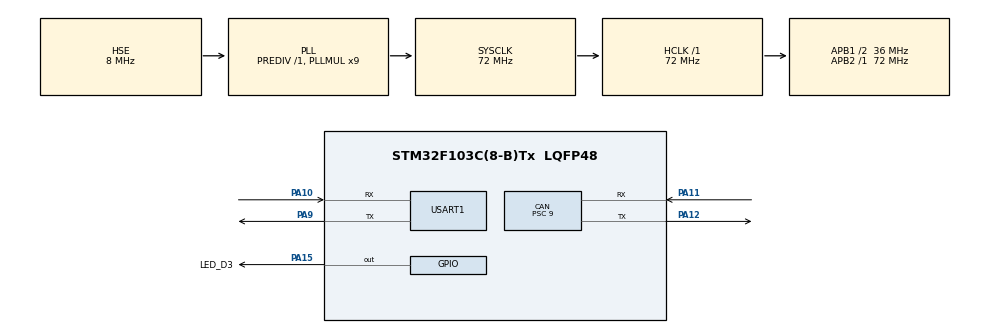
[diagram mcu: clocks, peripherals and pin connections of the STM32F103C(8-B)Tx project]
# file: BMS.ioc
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CAN.BS1=CAN_BS1_2TQ
CAN.BS2=CAN_BS2_5TQ
CAN.CalculateBaudRate=500000
CAN.CalculateTimeBit=2000
CAN.CalculateTimeQuantum=250.0
CAN.Prescaler=9
FREERTOS.Tasks01=defaultTask,24,128,StartDefaultTask,Default,NULL,Dynamic,NULL,NULL
FREERTOS.configTOTAL_HEAP_SIZE=10240
Mcu.Family=STM32F1
Mcu.Name=STM32F103C(8-B)Tx
Mcu.Package=LQFP48
NVIC.PriorityGroup=NVIC_PRIORITYGROUP_4
NVIC.TIM3_IRQn=true\:15\:0\:false\:false\:true\:false\:false\:true\:true
NVIC.TimeBase=TIM3_IRQn
NVIC.TimeBaseIP=TIM3
NVIC.USB_LP_CAN1_RX0_IRQn=true\:5\:0\:true\:false\:true\:true\:true\:true\:true
PA10.Mode=Asynchronous
PA10.Signal=USART1_RX
PA11.Mode=CAN_Activate
PA11.Signal=CAN_RX
PA12.Mode=CAN_Activate
PA12.Signal=CAN_TX
PA13.Mode=Serial_Wire
PA13.Signal=SYS_JTMS-SWDIO
PA14.Mode=Serial_Wire
PA14.Signal=SYS_JTCK-SWCLK
PA15.GPIO_Label=LED_D3
PA15.GPIO_Speed=GPIO_SPEED_FREQ_LOW
PA15.PinState=GPIO_PIN_SET
PA15.Signal=GPIO_Output
PA9.Mode=Asynchronous
PA9.Signal=USART1_TX
PD0-OSC_IN.Mode=HSE-External-Oscillator
PD0-OSC_IN.Signal=RCC_OSC_IN
PD1-OSC_OUT.Mode=HSE-External-Oscillator
PD1-OSC_OUT.Signal=RCC_OSC_OUT
ProjectManager.HeapSize=0x200
ProjectManager.StackSize=0x400
ProjectManager.TargetToolchain=MDK-ARM V5.32
RCC.AHBFreq_Value=72000000
RCC.APB1CLKDivider=RCC_HCLK_DIV2
RCC.APB1Freq_Value=36000000
RCC.APB1TimFreq_Value=72000000
RCC.APB2Freq_Value=72000000
RCC.APB2TimFreq_Value=72000000
RCC.HCLKFreq_Value=72000000
RCC.PLLMUL=RCC_PLL_MUL9
RCC.PLLSourceVirtual=RCC_PLLSOURCE_HSE
RCC.SYSCLKFreq_VALUE=72000000
RCC.SYSCLKSource=RCC_SYSCLKSOURCE_PLLCLK
RCC.USBFreq_Value=72000000
USART1.VirtualMode=VM_ASYNC
VP_FREERTOS_VS_CMSIS_V2.Mode=CMSIS_V2
VP_SYS_VS_tim3.Mode=TIM3
board=custom

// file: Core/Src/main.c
/* USER CODE BEGIN Header */
/**
  ******************************************************************************
  * @file           : main.c
  * @brief          : Main program body
  ******************************************************************************
  * @attention
  *
  * Copyright (c) 2026 STMicroelectronics.
  * All rights reserved.
  *
  * This software is licensed under terms that can be found in the LICENSE file
  * in the root directory of this software component.
  * If no LICENSE file comes with this software, it is provided AS-IS.
  *
  ******************************************************************************
  */
/* USER CODE END Header */
#include "main.h"
#include "cmsis_os.h"
#include "can.h"
#include "usart.h"
#include "gpio.h"

void SystemClock_Config(void);
void MX_FREERTOS_Init(void);

int main(void)
{

  /* MCU Configuration--------------------------------------------------------*/

  /* Reset of all peripherals, Initializes the Flash interface and the Systick. */
  HAL_Init();

  /* Configure the system clock */
  SystemClock_Config();

  /* Initialize all configured peripherals */
  MX_GPIO_Init();
  MX_USART1_UART_Init();
  MX_CAN_Init();

  /* Init scheduler */
  osKernelInitialize();

  /* Call init function for freertos objects (in cmsis_os2.c) */
  MX_FREERTOS_Init();

  /* Start scheduler */
  osKernelStart();

  /* We should never get here as control is now taken by the scheduler */

  /* Infinite loop */
  while (1)
  {

  }
}

void SystemClock_Config(void)
{
  RCC_OscInitTypeDef RCC_OscInitStruct = {0};
  RCC_ClkInitTypeDef RCC_ClkInitStruct = {0};

  /** Initializes the RCC Oscillators according to the specified parameters
  * in the RCC_OscInitTypeDef structure.
  */
  RCC_OscInitStruct.OscillatorType = RCC_OSCILLATORTYPE_HSE;
  RCC_OscInitStruct.HSEState = RCC_HSE_ON;
  RCC_OscInitStruct.HSEPredivValue = RCC_HSE_PREDIV_DIV1;
  RCC_OscInitStruct.HSIState = RCC_HSI_ON;
  RCC_OscInitStruct.PLL.PLLState = RCC_PLL_ON;
  RCC_OscInitStruct.PLL.PLLSource = RCC_PLLSOURCE_HSE;
  RCC_OscInitStruct.PLL.PLLMUL = RCC_PLL_MUL9;
  if (HAL_RCC_OscConfig(&RCC_OscInitStruct) != HAL_OK)
  {
    Error_Handler();
  }

  /** Initializes the CPU, AHB and APB buses clocks
  */
  RCC_ClkInitStruct.ClockType = RCC_CLOCKTYPE_HCLK|RCC_CLOCKTYPE_SYSCLK
                              |RCC_CLOCKTYPE_PCLK1|RCC_CLOCKTYPE_PCLK2;
  RCC_ClkInitStruct.SYSCLKSource = RCC_SYSCLKSOURCE_PLLCLK;
  RCC_ClkInitStruct.AHBCLKDivider = RCC_SYSCLK_DIV1;
  RCC_ClkInitStruct.APB1CLKDivider = RCC_HCLK_DIV2;
  RCC_ClkInitStruct.APB2CLKDivider = RCC_HCLK_DIV1;

  if (HAL_RCC_ClockConfig(&RCC_ClkInitStruct, FLASH_LATENCY_2) != HAL_OK)
  {
    Error_Handler();
  }
}

void HAL_TIM_PeriodElapsedCallback(TIM_HandleTypeDef *htim)
{
  if (htim->Instance == TIM3) {
    HAL_IncTick();
  }
}

void Error_Handler(void)
{
  __disable_irq();
  while (1)
  {
  }
}

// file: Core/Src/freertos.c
/* USER CODE BEGIN Header */
/**
  ******************************************************************************
  * File Name          : freertos.c
  * Description        : Code for freertos applications
  ******************************************************************************
  * @attention
  *
  * Copyright (c) 2026 STMicroelectronics.
  * All rights reserved.
  *
  * This software is licensed under terms that can be found in the LICENSE file
  * in the root directory of this software component.
  * If no LICENSE file comes with this software, it is provided AS-IS.
  *
  ******************************************************************************
  */
/* USER CODE END Header */

#include "FreeRTOS.h"
#include "task.h"
#include "main.h"
#include "cmsis_os.h"

/* USER CODE BEGIN Includes */
#include "TaskInit.h"
/* USER CODE END Includes */

/* Definitions for defaultTask */
osThreadId_t defaultTaskHandle;
const osThreadAttr_t defaultTask_attributes = {
  .name = "defaultTask",
  .stack_size = 128 * 4,
  .priority = (osPriority_t) osPriorityNormal,
};

void StartDefaultTask(void *argument);

void MX_FREERTOS_Init(void); /* (MISRA C 2004 rule 8.1) */

void MX_FREERTOS_Init(void) {

  /* Create the thread(s) */
  /* creation of defaultTask */
  defaultTaskHandle = osThreadNew(StartDefaultTask, NULL, &defaultTask_attributes);

}

void StartDefaultTask(void *argument)
{
  /* USER CODE BEGIN StartDefaultTask */
  TaskInit();
  /* Infinite loop */
  for(;;)
  {
    HAL_GPIO_TogglePin(LED_D3_GPIO_Port, LED_D3_Pin);
    osDelay(500);
  }
  /* USER CODE END StartDefaultTask */
}
